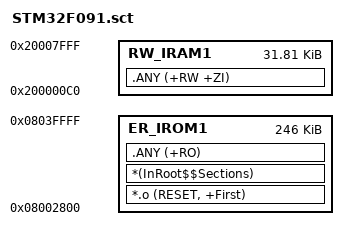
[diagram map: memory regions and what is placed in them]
; *************************************************************
; *** Scatter-Loading Description File generated by uVision ***
; *************************************************************
; First 10kb in ROM is reserved for the OpenBLT bootloader
LR_IROM1 0x08002800 0x0003D800  {    ; load region size_region
  ER_IROM1 0x08002800 0x0003D800  {  ; load address = execution address
   *.o (RESET, +First)
   *(InRoot$$Sections)
   .ANY (+RO)
  }
  RW_IRAM1 0x200000C0 0x00007F40  {  ; RW data - First 192 bytes reserved for OpenBLT
   .ANY (+RW +ZI)
  }
}

